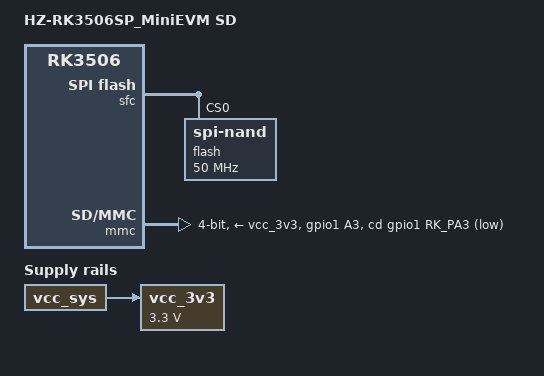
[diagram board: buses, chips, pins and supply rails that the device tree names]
// SPDX-License-Identifier: (GPL-2.0+ OR MIT)
/*
 * Copyright (c) 2025 HZHY Electronics Co., Ltd.
 * HZ-RK3506SP MiniEVM — SD card boot variant (kernel + rootfs from SD).
 */

/dts-v1/;
#include "HZ-RK3506SP_MiniEVM.dtsi"

/ {
	model = "HZ-RK3506SP_MiniEVM SD";
	compatible = "rockchip,rk3506-evb1-v10", "rockchip,rk3506";
	chosen {
		/* rootfs on SD partition 2 (squashfs). The vendor U-Boot 2017.09 does
		 * NOT propagate env bootargs into the kernel DT /chosen, so the
		 * bootscript's `setenv bootargs root=PARTUUID=...` is ignored — root
		 * must live here, not in bootscript. */
		bootargs = "earlycon=uart8250,mmio32,0xff0a0000 console=ttyS0,1500000 root=/dev/mmcblk0p2 rootfstype=squashfs rootwait net.ifnames=0";
	};
	/delete-node/ sdio-pwrseq;
	vcc_3v3: vcc-3v3 {
		compatible = "regulator-fixed";
		regulator-name = "vcc_3v3";
		regulator-always-on;
		regulator-boot-on;
		regulator-min-microvolt = <3300000>;
		regulator-max-microvolt = <3300000>;
		vin-supply = <&vcc_sys>;
	};
	/* vccio_sd is the fixed always-on 3.3V regulator the dtsi already declares,
	 * which is what sheet 07 shows: the card rail is VCC3V3, VDD_ADJ_SD_OUT only
	 * carries R129 100K plus NC/10K jumpers, and no GPIO selects the voltage.
	 */
};

&sfc {
	status = "okay";
	flash@0 {
		compatible = "spi-nand";
		reg = <0>;
		spi-max-frequency = <50000000>;
		spi-rx-bus-width = <4>;
		spi-tx-bus-width = <1>;
	};
};

/* SD slot - this is also the boot medium, so the card must not disappear
 * under the mounted rootfs. broken-cd made dw_mmc poll at 1 Hz and every
 * rescan re-negotiated the bus, which is what tore down mmcblk0 in uart.log
 * ("card e624 removed" at 23.2s, then squashfs/f2fs I/O errors). Sheet 07
 * puts SDMMC0_DET_L on GPIO1_A3 - floating with the card out, GND with it in,
 * so the pad needs its internal pull-up - hence a real cd-gpios here, the same
 * as the NAND variants. max-frequency holds the bus at 25 MHz; the 50 MHz
 * High-Speed clock the vendor file assumed is not proven on this board.
 * The card runs 3.3V only, hence no-1-8-v and no sd-uhs-sdr104. */
&mmc {
	/delete-property/ no-sd;
	/delete-property/ ignore-pm-notify;
	/delete-property/ keep-power-in-suspend;
	/delete-property/ non-removable;
	/delete-property/ mmc-pwrseq;
	cap-sd-highspeed;
	bus-width = <4>;
	no-sdio;
	no-mmc;
	no-1-8-v;
	max-frequency = <25000000>;
	cd-gpios = <&gpio1 RK_PA3 GPIO_ACTIVE_LOW>;
	disable-wp;
	pinctrl-names = "default";
	pinctrl-0 = <&sdmmc_clk_pins &sdmmc_cmd_pins &sdmmc_bus4_pins &sd_det>;
	vmmc-supply = <&vcc_3v3>;
	vqmmc-supply = <&vccio_sd>;
	status = "okay";
};

&pinctrl {
	sdmmc {
		sd_det: sd-det {
			rockchip,pins = <1 RK_PA3 RK_FUNC_GPIO &pcfg_pull_up>;
		};
	};
};
